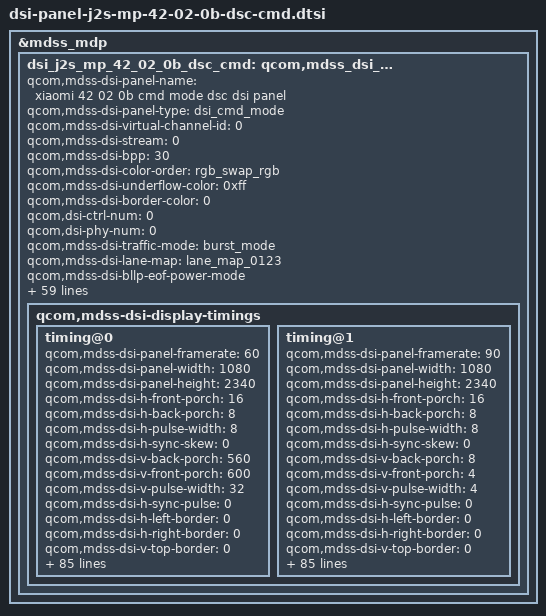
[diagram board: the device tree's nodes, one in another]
&mdss_mdp {
	dsi_j2s_mp_42_02_0b_dsc_cmd: qcom,mdss_dsi_j2s_mp_42_02_0b_dsc_cmd {
		qcom,mdss-dsi-panel-name = "xiaomi 42 02 0b cmd mode dsc dsi panel";
		qcom,mdss-dsi-panel-type = "dsi_cmd_mode";
		qcom,mdss-dsi-virtual-channel-id = <0>;
		qcom,mdss-dsi-stream = <0>;
		qcom,mdss-dsi-bpp = <30>;
		qcom,mdss-dsi-color-order = "rgb_swap_rgb";
		qcom,mdss-dsi-underflow-color = <0xff>;
		qcom,mdss-dsi-border-color = <0>;

		qcom,dsi-ctrl-num = <0>;
		qcom,dsi-phy-num = <0>;

		qcom,mdss-dsi-traffic-mode = "burst_mode";
		qcom,mdss-dsi-lane-map = "lane_map_0123";
		qcom,mdss-dsi-bllp-eof-power-mode;
		qcom,mdss-dsi-bllp-power-mode;
		qcom,mdss-dsi-lane-0-state;
		qcom,mdss-dsi-lane-1-state;
		qcom,mdss-dsi-lane-2-state;
		qcom,mdss-dsi-lane-3-state;
		qcom,mdss-dsi-dma-trigger = "trigger_sw";
		qcom,mdss-dsi-mdp-trigger = "none";
		qcom,mdss-dsi-reset-sequence = <1 1>, <0 1>, <1 10>;
		qcom,mdss-pan-physical-width-dimension = <710>;
		qcom,mdss-pan-physical-height-dimension = <1537>;
		qcom,mdss-dsi-te-pin-select = <1>;
		qcom,mdss-dsi-wr-mem-start = <0x2c>;
		qcom,mdss-dsi-wr-mem-continue = <0x3c>;
		qcom,mdss-dsi-te-dcs-command = <1>;
		qcom,mdss-dsi-te-check-enable;
		qcom,mdss-dsi-te-using-te-pin;
		qcom,mdss-dsi-tx-eot-append;
		qcom,mdss-dsi-lp11-init;

		qcom,mdss-dsi-panel-hdr-enabled;
		qcom,mdss-dsi-panel-hdr-color-primaries = <14500 15500 32000
			17000 15500 30000 8000 3000>;
		qcom,mdss-dsi-panel-peak-brightness = <4200000>;
		qcom,mdss-dsi-panel-blackness-level = <3230>;

		qcom,bl-update-flag = "delay_until_first_frame";

		qcom,esd-check-enabled;
		qcom,mdss-dsi-panel-status-check-mode = "reg_read";
		qcom,mdss-dsi-panel-status-offset-command = [
			39 00 00 00 00 00 05 FF AA 55 A5 81
			15 01 00 00 00 00 02 6F 0F];
		qcom,mdss-dsi-panel-status-command = [
			06 01 00 01 00 00 01 FA
			06 01 00 01 00 00 01 91];
		qcom,mdss-dsi-panel-status-read-length = <1 18>;
		qcom,mdss-dsi-panel-max-error-count = <3>;
		qcom,mdss-dsi-panel-status-value = <0x00>,
				<0xAB 0x28 0x00 0x0C 0xC2 0x00 0x03 0x1C 0x01 0x7E 0x00 0x0F 0x08 0xBB 0x04 0x3D 0x10 0xF0>;
		qcom,mdss-dsi-panel-status-command-state = "dsi_lp_mode";
		qcom,mdss-dsi-panel-status-offset-command-state = "dsi_lp_mode";

		qcom,mdss-dsi-display-timings {
			timing@0{
				qcom,mdss-dsi-panel-framerate = <60>;
				qcom,mdss-dsi-panel-width = <1080>;
				qcom,mdss-dsi-panel-height = <2340>;
				qcom,mdss-dsi-h-front-porch = <16>;
				qcom,mdss-dsi-h-back-porch = <8>;
				qcom,mdss-dsi-h-pulse-width = <8>;
				qcom,mdss-dsi-h-sync-skew = <0>;
				qcom,mdss-dsi-v-back-porch = <560>;
				qcom,mdss-dsi-v-front-porch = <600>;
				qcom,mdss-dsi-v-pulse-width = <32>;
				qcom,mdss-dsi-h-sync-pulse = <0>;
				qcom,mdss-dsi-h-left-border = <0>;
				qcom,mdss-dsi-h-right-border = <0>;
				qcom,mdss-dsi-v-top-border = <0>;
				qcom,mdss-dsi-v-bottom-border = <0>;
				qcom,mdss-dsi-panel-clockrate = <682000000>;
				qcom,mdss-dsi-panel-jitter = <0x5 0x1>;
				qcom,mdss-mdp-transfer-time-us = <9500>;
				qcom,mdss-dsi-on-command = [
					39 00 00 00 00 00 05 3B 00 18 00 18
					39 00 00 00 00 00 02 03 01
					39 00 00 00 00 00 02 90 01
					39 00 00 00 00 00 13 91 89 28 00 0C C2 00 03 1C 01 7E 00 0F 08 BB 04 3D 10 F0
					05 01 00 00 00 00 02 2C 00
					39 00 00 00 00 00 06 F0 55 AA 52 08 00
					39 00 00 00 00 00 04 C0 66 F3 C1
					39 00 00 00 00 00 02 6F 06
					39 01 00 00 00 00 04 B5 2B 0A 32
					39 00 00 00 00 00 02 6F 0B
					39 01 00 00 00 00 04 B5 33 23 2B
					39 00 00 00 00 00 06 F0 55 AA 52 08 01
					39 00 00 00 00 00 02 6F 01
					39 00 00 00 00 00 04 D2 00 22 33
					39 00 00 00 00 00 06 CE 00 00 01 00 04
					39 00 00 00 00 00 08 C3 95 01 92 D0 22 02 00
					39 00 00 00 00 00 02 53 20
					05 00 00 00 00 00 02 35 00
					39 00 00 00 00 00 05 2A 00 00 04 37
					39 01 00 00 00 00 05 2B 00 00 09 23
					39 00 00 00 00 00 05 FF AA 55 A5 81
					39 00 00 00 00 00 02 6F 0F
					39 00 00 00 00 00 02 FD 01
					39 00 00 00 00 00 02 6F 10
					39 00 00 00 00 00 02 FD 41
					39 01 00 00 00 00 02 2F 01
					05 01 00 00 78 00 02 11 00
					05 01 00 00 14 00 02 29 00];
				qcom,mdss-dsi-off-command = [
					05 01 00 00 00 00 02 28 00
					05 01 00 00 78 00 02 10 00];
				qcom,mdss-dsi-on-command-state = "dsi_lp_mode";
				qcom,mdss-dsi-off-command-state = "dsi_lp_mode";

				qcom,mdss-dsi-timing-switch-command = [
					/* Enter 60Hz */
					15 01 00 00 00 00 02 2F 01];
				qcom,mdss-dsi-timing-switch-command-state = "dsi_lp_mode";

				qcom,mdss-dsi-nolp-command = [
					/* close aod backlight */
					15 00 00 00 00 00 02 6F 02
					39 01 00 00 00 00 03 51 00 00
					/* Aod to Normal */
					39 00 00 00 00 00 06 F0 55 AA 52 08 00 /* Set page 0 */
					15 00 00 00 00 00 02 B2 58
					15 00 00 00 00 00 02 65 00
					05 00 00 00 00 00 02 38 00
					05 01 00 00 00 00 02 2C 00];
				qcom,mdss-dsi-nolp-command-state = "dsi_lp_mode";

				qcom,compression-mode = "dsc";
				qcom,mdss-dsc-version = <0x11>;
				qcom,mdss-dsc-scr-version = <0x0>;
				qcom,mdss-dsc-slice-height = <12>;
				qcom,mdss-dsc-slice-width = <1080>;
				qcom,mdss-dsc-slice-per-pkt = <2>;
				qcom,mdss-dsc-bit-per-component = <10>;
				qcom,mdss-dsc-bit-per-pixel = <8>;
				qcom,mdss-dsc-block-prediction-enable;
			};
			timing@1{
				qcom,mdss-dsi-panel-framerate = <90>;
				qcom,mdss-dsi-panel-width = <1080>;
				qcom,mdss-dsi-panel-height = <2340>;
				qcom,mdss-dsi-h-front-porch = <16>;
				qcom,mdss-dsi-h-back-porch = <8>;
				qcom,mdss-dsi-h-pulse-width = <8>;
				qcom,mdss-dsi-h-sync-skew = <0>;
				qcom,mdss-dsi-v-back-porch = <8>;
				qcom,mdss-dsi-v-front-porch = <4>;
				qcom,mdss-dsi-v-pulse-width = <4>;
				qcom,mdss-dsi-h-sync-pulse = <0>;
				qcom,mdss-dsi-h-left-border = <0>;
				qcom,mdss-dsi-h-right-border = <0>;
				qcom,mdss-dsi-v-top-border = <0>;
				qcom,mdss-dsi-v-bottom-border = <0>;
				qcom,mdss-dsi-panel-clockrate = <682000000>;
				qcom,mdss-dsi-panel-jitter = <0x5 0x1>;
				qcom,mdss-mdp-transfer-time-us = <9500>;
				qcom,mdss-dsi-on-command = [
					39 00 00 00 00 00 05 3B 00 18 00 18
					39 00 00 00 00 00 02 03 01
					39 00 00 00 00 00 02 90 01
					39 00 00 00 00 00 13 91 89 28 00 0C C2 00 03 1C 01 7E 00 0F 08 BB 04 3D 10 F0
					05 01 00 00 00 00 02 2C 00
					39 00 00 00 00 00 06 F0 55 AA 52 08 00
					39 00 00 00 00 00 04 C0 66 F3 C1
					39 00 00 00 00 00 02 6F 06
					39 01 00 00 00 00 04 B5 2B 0A 32
					39 00 00 00 00 00 02 6F 0B
					39 01 00 00 00 00 04 B5 33 23 2B
					39 00 00 00 00 00 06 F0 55 AA 52 08 01
					39 00 00 00 00 00 04 D2 00 22 33
					39 00 00 00 00 00 06 CE 00 00 01 00 04
					39 00 00 00 00 00 08 C3 95 01 92 D0 22 02 00
					39 00 00 00 00 00 02 53 20
					05 00 00 00 00 00 02 35 00
					39 00 00 00 00 00 05 2A 00 00 04 37
					39 01 00 00 00 00 05 2B 00 00 09 23
					39 00 00 00 00 00 05 FF AA 55 A5 81
					39 00 00 00 00 00 02 6F 0F
					39 00 00 00 00 00 02 FD 01
					39 00 00 00 00 00 02 6F 10
					39 00 00 00 00 00 02 FD 41
					39 01 00 00 00 00 02 2F 02
					05 01 00 00 78 00 02 11 00
					05 01 00 00 14 00 02 29 00];
				qcom,mdss-dsi-off-command = [
					05 01 00 00 00 00 02 28 00
					05 01 00 00 78 00 02 10 00];
				qcom,mdss-dsi-on-command-state = "dsi_lp_mode";
				qcom,mdss-dsi-off-command-state = "dsi_lp_mode";

				qcom,mdss-dsi-timing-switch-command = [
					/* Enter 90Hz */
					15 01 00 00 00 00 02 2F 02];
				qcom,mdss-dsi-timing-switch-command-state = "dsi_lp_mode";

				qcom,mdss-dsi-nolp-command = [
					/* close aod backlight */
					15 00 00 00 00 00 02 6F 02
					39 01 00 00 00 00 03 51 00 00
					/* Aod to Normal */
					39 00 00 00 00 00 06 F0 55 AA 52 08 00 /* Set page 0 */
					15 00 00 00 00 00 02 B2 58
					15 00 00 00 00 00 02 65 00
					05 00 00 00 00 00 02 38 00
					05 01 00 00 00 00 02 2C 00
					/* Enter 90Hz */
					15 01 00 00 00 00 02 2F 02];
				qcom,mdss-dsi-nolp-command-state = "dsi_lp_mode";

				qcom,compression-mode = "dsc";
				qcom,mdss-dsc-version = <0x11>;
				qcom,mdss-dsc-scr-version = <0x0>;
				qcom,mdss-dsc-slice-height = <12>;
				qcom,mdss-dsc-slice-width = <1080>;
				qcom,mdss-dsc-slice-per-pkt = <2>;
				qcom,mdss-dsc-bit-per-component = <10>;
				qcom,mdss-dsc-bit-per-pixel = <8>;
				qcom,mdss-dsc-block-prediction-enable;
			};
		};
	};
};

&dsi_j2s_mp_42_02_0b_dsc_cmd {
	mi,panel-id = <0x4A32 0x00420201>;
	mi,feature-enabled;
	mi,mdss-dsi-bl-dcs-big-endian-type;
	mi,mdss-dsi-panel-hbm-51-ctrl-flag;
	mi,mdss-dsi-panel-hbm-off-51-index = <1>;
	mi,mdss-dsi-panel-fod-off-51-index = <1>;
	mi,mdss-dsi-panel-disp-rate-gpio = <&tlmm 50 0>;
	/* IRQF_ONESHOT | IRQF_TRIGGER_RISING */
	/* trig-flags: falling-0x0002 rasing-0x0001 */
	mi,esd-err-irq-gpio = <&tlmm 51 0x2002>;

	/* White Color Coordinate */
	mi,mdss-dsi-white-point-read-enabled;
	mi,mdss-dsi-white-point-register-read-length = <8>;
	mi,mdss-dsi-white-point-info-index = <0>;
	mi,mdss-dsi-white-point-info-length = <8>;

	mi,mdss-dsi-panel-dc-type = <0>;

	mi,mdss-panel-on-dimming-delay = <120>;

	mi,mdss-dsi-panel-fod-dimlayer-enabled;

	mi,mdss-dsi-dimlayer-brightness-alpha-lut-item-count = <21>;
	mi,mdss-dsi-dimlayer-brightness-alpha-lut =
	/* brightness  alpha */
		<0          0xFF
		 4          0xEB
		 8          0xEA
		 12         0xE9
		 13         0xE8
		 20         0xE5
		 24         0xE3
		 30         0xE0
		 68         0xD0
		 133        0xC0
		 218        0xB0
		 328        0xA0
		 486        0x90
		 642        0x80
		 832        0x70
		 1043       0x60
		 1267       0x50
		 1500       0x40
		 1770       0x30
		 2000       0x24
		 2047       0x21>;

	qcom,mdss-dsi-display-timings {
		timing@0{
			mi,mdss-dsi-doze-hbm-command = [
				/* Enter 60Hz */
				15 01 00 00 00 00 02 2F 01
				/* AOD Mode On */
				39 00 00 00 00 00 06 F0 55 AA 52 08 00
				15 00 00 00 00 00 02 B2 08
				05 00 00 00 00 00 02 39 00
				15 00 00 00 00 00 02 65 01
				05 01 00 00 00 00 02 2C 00
				/* 60 nit*/
				15 00 00 00 00 00 02 6F 02
				39 01 00 00 00 00 03 51 0F FF];
			mi,mdss-dsi-doze-lbm-command = [
				/* Enter 60Hz */
				15 01 00 00 00 00 02 2F 01
				/* AOD Mode On */
				39 00 00 00 00 00 06 F0 55 AA 52 08 00
				15 00 00 00 00 00 02 B2 08
				05 00 00 00 00 00 02 39 00
				15 00 00 00 00 00 02 65 01
				05 01 00 00 00 00 02 2C 00
				/* 5 nit */
				15 00 00 00 00 00 02 6F 02
				39 01 00 00 00 00 03 51 01 55];
			mi,mdss-dsi-doze-hbm-command-state = "dsi_lp_mode";
			mi,mdss-dsi-doze-lbm-command-state = "dsi_lp_mode";

			mi,mdss-dsi-hbm-on-command = [
				/* Dimming On */
				15 00 00 00 00 00 02 53 28
				/* HBM Mode 800 nit */
				39 01 00 00 00 00 05 51 0F FF 00 00];
			mi,mdss-dsi-hbm-off-command = [
				/* Dimming On */
				15 00 00 00 00 00 02 53 28
				/* Normal Mode */
				/* parameter will be updated base on last brightness */
				39 01 00 00 00 00 05 51 07 FF 00 00];
			mi,mdss-dsi-hbm-on-command-state = "dsi_lp_mode";
			mi,mdss-dsi-hbm-off-command-state = "dsi_lp_mode";

			/* aod mode -> hbm on for fingerprint unlock */
			mi,mdss-dsi-hbm-fod-on-command = [
				/* Dimming Off */
				15 00 00 00 00 00 02 53 20
				/* HBM Mode 700 nit */
				39 01 00 00 00 00 05 51 0F 8F 00 00
				/* Aod to Normal */
				39 00 00 00 00 00 06 F0 55 AA 52 08 00 /* Set page 0 */
				15 00 00 00 00 00 02 B2 58
				15 00 00 00 00 00 02 65 00
				05 00 00 00 00 00 02 38 00
				05 01 00 00 00 00 02 2C 00];
			mi,mdss-dsi-hbm-fod-off-command = [
				/* Dimming Off */
				15 00 00 00 00 00 02 53 20
				/* Normal Mode */
				/* parameter will be updated base on last brightness */
				39 01 00 00 00 00 05 51 07 FF 00 00];
			mi,mdss-dsi-hbm-fod-on-command-state = "dsi_lp_mode";
			mi,mdss-dsi-hbm-fod-off-command-state = "dsi_lp_mode";

			mi,mdss-dsi-hbm-hdr-on-command = [
				/* VI Setting voltage -3.5V */
				39 01 00 00 00 00 06 F0 55 AA 52 08 01 /* Set page 1 */
				39 00 00 00 00 00 09 B9 1F 1F 1F 1F 1F 1F 1F 1F
				/* Dimming On */
				15 00 00 00 00 00 02 53 28
				/* HBM Mode 800 nit */
				39 01 00 00 00 00 05 51 0F FF 00 00
				/* ELVSS SWIRE =-4.5V */
				15 01 00 00 00 00 02 6F 07
				15 01 00 00 00 00 02 B5 0A];
			mi,mdss-dsi-hbm-hdr-off-command = [
				/* Dimming On */
				15 01 00 00 00 00 02 53 28
				/* Normal Mode */
				/* parameter will be updated base on last brightness */
				39 01 00 00 00 00 05 51 07 FF 00 00];
			mi,mdss-dsi-hbm-hdr-on-command-state = "dsi_lp_mode";
			mi,mdss-dsi-hbm-hdr-off-command-state = "dsi_lp_mode";

			mi,mdss-dsi-dimmingon-command = [15 01 00 00 00 00 02 53 28];
			mi,mdss-dsi-dimmingon-command-state = "dsi_lp_mode";
			mi,mdss-dsi-dimmingoff-command = [15 01 00 00 00 00 02 53 20];
			mi,mdss-dsi-dimmingoff-command-state = "dsi_lp_mode";

			mi,mdss-dsi-white-point-read-command = [06 01 00 00 01 00 02 DF 00];
			mi,mdss-dsi-white-point-read-command-state = "dsi_lp_mode";

			mi,mdss-dsi-switch-page4-command = [
				/* Set page 4 */
				39 01 00 00 00 00 06 F0 55 AA 52 08 04];
			mi,mdss-dsi-dc-read-command = [
				/* Read DC_LUT */
				06 01 00 00 00 00 02 D2 00];
			mi,mdss-dsi-switch-page4-command-state = "dsi_lp_mode";
			mi,mdss-dsi-dc-read-command-state = "dsi_lp_mode";

			mi,mdss-dsi-dc-on-command = [
				39 00 00 00 00 00 06 F0 55 AA 52 08 00 /* Set page 0 */
				15 00 00 00 00 00 02 B2 D8
				15 00 00 00 00 00 02 6F 0F
				39 00 00 00 00 00 03 B2 00 00
				39 00 00 00 00 00 25 B3 00 00 00 00 00 00 00 00 00 00 00 00 00 00 00 00 00 00 00 00 00 00 00 00 00 00 00 00 00 00 00 00 07 FF 0F FF
				39 00 00 00 00 00 06 F0 55 AA 52 08 04 /* Set page 4 */
				39 01 00 00 00 00 4C D2
					12 1F 1F 12 10 19 1F 1F 19 20 30 30 30 30 2B 3F 3F 3F 3F 38 5F 5F 5F 5A 60
					2F 20 20 30 0D 19 25 25 23 25 3F 3F 3F 3F 2F 45 45 45 45 45 65 65 65 6F 68
					1A 20 20 20 08 1F 1F 1F 1F 10 2F 2F 2F 2F 24 3F 3F 3F 3F 38 9F 88 74 5F 60
				39 01 00 00 00 00 4C D4
					1F 20 20 20 14 20 30 30 1A 20 3F 3F 3F 30 2B 5F 5F 5F 50 3B 5F 5F 5F 5F 6F
					40 2D 2D 2D 0E 20 35 35 30 20 36 36 36 36 36 58 58 58 58 4A 6F 6F 6F 6F 7F
					10 1B 1B 1B 0D 25 25 25 25 18 36 36 36 36 2B 4F 4F 4F 4F 3B 5F 5F 5F 5F 5F];
			mi,mdss-dsi-dc-on-command-state = "dsi_lp_mode";
			mi,mdss-dsi-dc-off-command = [
				39 00 00 00 00 00 06 F0 55 AA 52 08 00 /* Set page 0 */
				15 00 00 00 00 00 02 B2 58
				15 00 00 00 00 00 02 6F 0F
				39 00 00 00 00 00 03 B2 20 20
				39 00 00 00 00 00 25 B3 00 08 00 21 00 21 00 52 00 52 00 76 00 76 00 AE 00 AE 01 0E 01 0E 01 C2 01 C2 03 33 03 33 07 FF 07 FF 0F FF
				39 00 00 00 00 00 06 F0 55 AA 52 08 04 /* Set page 4 */
				39 01 00 00 00 00 4C D2
					98 60 30 1F 10 98 40 40 1F 20 60 48 44 30 2B 70 48 70 3F 38 3F 78 74 5F 60
					98 60 4A 30 0D 98 95 50 20 25 68 60 54 3F 2F FA 68 74 45 45 95 88 84 65 68
					98 40 40 20 08 98 40 40 1F 10 68 38 44 2F 24 88 38 64 3F 38 9F 88 74 5F 60
				39 01 00 00 00 00 4C D4
					FF 88 50 20 14 FF 58 50 30 20 FF 60 5F 3F 2B 7F 72 6F 5F 3B BF 92 7F 5F 6F
					FF 8A 5F 2D 0E FF B0 9F 50 20 FF 95 62 50 36 FF 65 7F 58 4A F5 A8 8F 6F 7F
					FF 88 38 1B 0D FF 48 28 25 18 FF 46 42 36 2B B0 82 5F 4F 3B 6F 82 7F 5F 5F];
			mi,mdss-dsi-dc-off-command-state = "dsi_lp_mode";

			mi,mdss-dsi-aod-to-dc-on-command = [
				39 00 00 00 00 00 06 F0 55 AA 52 08 00 /* Set page 0 */
				15 00 00 00 00 00 02 B2 D8
				15 00 00 00 00 00 02 6F 0F
				39 00 00 00 00 00 03 B2 00 00
				39 00 00 00 00 00 25 B3 00 00 00 00 00 00 00 00 00 00 00 00 00 00 00 00 00 00 00 00 00 00 00 00 00 00 00 00 00 00 00 00 07 FF 0F FF
				39 00 00 00 00 00 06 F0 55 AA 52 08 04 /* Set page 4 */
				39 01 00 00 00 00 4C D2
					12 1F 1F 12 10 19 1F 1F 19 20 30 30 30 30 2B 3F 3F 3F 3F 38 5F 5F 5F 5A 60
					2F 20 20 30 0D 19 25 25 23 25 3F 3F 3F 3F 2F 45 45 45 45 45 65 65 65 6F 68
					1A 20 20 20 08 1F 1F 1F 1F 10 2F 2F 2F 2F 24 3F 3F 3F 3F 38 9F 88 74 5F 60
				39 01 00 00 00 00 4C D4
					1F 20 20 20 14 20 30 30 1A 20 3F 3F 3F 30 2B 5F 5F 5F 50 3B 5F 5F 5F 5F 6F
					40 2D 2D 2D 0E 20 35 35 30 20 36 36 36 36 36 58 58 58 58 4A 6F 6F 6F 6F 7F
					10 1B 1B 1B 0D 25 25 25 25 18 36 36 36 36 2B 4F 4F 4F 4F 3B 5F 5F 5F 5F 5F];
			mi,mdss-dsi-aod-to-dc-on-command-state = "dsi_lp_mode";
		};
		timing@1{
			mi,mdss-dsi-doze-hbm-command = [
				/* Enter 60Hz */
				15 01 00 00 00 00 02 2F 01
				/* AOD Mode On */
				39 00 00 00 00 00 06 F0 55 AA 52 08 00
				15 00 00 00 00 00 02 B2 08
				05 00 00 00 00 00 02 39 00
				15 00 00 00 00 00 02 65 01
				05 01 00 00 00 00 02 2C 00
				/* 60 nit */
				15 00 00 00 00 00 02 6F 02
				39 01 00 00 00 00 03 51 0F FF];
			mi,mdss-dsi-doze-lbm-command = [
				/* Enter 60Hz */
				15 01 00 00 00 00 02 2F 01
				/* AOD Mode On */
				39 00 00 00 00 00 06 F0 55 AA 52 08 00
				15 00 00 00 00 00 02 B2 08
				05 00 00 00 00 00 02 39 00
				15 00 00 00 00 00 02 65 01
				05 01 00 00 00 00 02 2C 00
				/* 5 nit */
				15 00 00 00 00 00 02 6F 02
				39 01 00 00 00 00 03 51 01 55];
			mi,mdss-dsi-doze-hbm-command-state = "dsi_lp_mode";
			mi,mdss-dsi-doze-lbm-command-state = "dsi_lp_mode";

			mi,mdss-dsi-hbm-on-command = [
				/* Dimming On */
				15 00 00 00 00 00 02 53 28
				/* HBM Mode 800 nit */
				39 01 00 00 00 00 05 51 0F FF 00 00];
			mi,mdss-dsi-hbm-off-command = [
				/* Dimming On */
				15 00 00 00 00 00 02 53 28
				/* Normal Mode */
				/* parameter will be updated base on last brightness */
				39 01 00 00 00 00 05 51 07 FF 00 00];
			mi,mdss-dsi-hbm-on-command-state = "dsi_lp_mode";
			mi,mdss-dsi-hbm-off-command-state = "dsi_lp_mode";

			/* aod mode -> hbm on for fingerprint unlock */
			mi,mdss-dsi-hbm-fod-on-command = [
				/* Dimming Off */
				15 00 00 00 00 00 02 53 20
				/* HBM Mode 700 nit */
				39 01 00 00 00 00 05 51 0F 8F 00 00
				/* Aod to Normal */
				39 00 00 00 00 00 06 F0 55 AA 52 08 00 /* Set page 0 */
				15 00 00 00 00 00 02 B2 58
				15 00 00 00 00 00 02 65 00
				05 00 00 00 00 00 02 38 00
				05 01 00 00 00 00 02 2C 00
				/* Enter 90Hz */
				15 01 00 00 00 00 02 2F 02];
			mi,mdss-dsi-hbm-fod-off-command = [
				/* Dimming Off */
				15 00 00 00 00 00 02 53 20
				/* Normal Mode */
				/* parameter will be updated base on last brightness */
				39 01 00 00 00 00 05 51 07 FF 00 00];
			mi,mdss-dsi-hbm-fod-on-command-state = "dsi_lp_mode";
			mi,mdss-dsi-hbm-fod-off-command-state = "dsi_lp_mode";

			mi,mdss-dsi-hbm-hdr-on-command = [
				/* VI Setting voltage -3.5V */
				39 01 00 00 00 00 06 F0 55 AA 52 08 01 /* Set page 1 */
				39 00 00 00 00 00 09 B9 1F 1F 1F 1F 1F 1F 1F 1F
				/* Dimming On */
				15 00 00 00 00 00 02 53 28
				/* HBM Mode 800 nit */
				39 01 00 00 00 00 05 51 0F FF 00 00
				/* ELVSS SWIRE =-4.5V */
				15 01 00 00 00 00 02 6F 07
				15 01 00 00 00 00 02 B5 0A];
			mi,mdss-dsi-hbm-hdr-off-command = [
				/* Dimming On */
				15 01 00 00 00 00 02 53 28
				/* Normal Mode */
				/* parameter will be updated base on last brightness */
				39 01 00 00 00 00 05 51 07 FF 00 00];
			mi,mdss-dsi-hbm-hdr-on-command-state = "dsi_lp_mode";
			mi,mdss-dsi-hbm-hdr-off-command-state = "dsi_lp_mode";

			mi,mdss-dsi-dimmingon-command = [15 01 00 00 00 00 02 53 28];
			mi,mdss-dsi-dimmingon-command-state = "dsi_lp_mode";
			mi,mdss-dsi-dimmingoff-command = [15 01 00 00 00 00 02 53 20];
			mi,mdss-dsi-dimmingoff-command-state = "dsi_lp_mode";

			mi,mdss-dsi-white-point-read-command = [06 01 00 00 01 00 02 DF 00];
			mi,mdss-dsi-white-point-read-command-state = "dsi_lp_mode";

			mi,mdss-dsi-switch-page4-command = [
				/* Set page 4 */
				39 01 00 00 00 00 06 F0 55 AA 52 08 04];
			mi,mdss-dsi-dc-read-command = [
				/* Read DC_LUT */
				06 01 00 00 00 00 02 D2 00];
			mi,mdss-dsi-switch-page4-command-state = "dsi_lp_mode";
			mi,mdss-dsi-dc-read-command-state = "dsi_lp_mode";

			mi,mdss-dsi-dc-on-command = [
				39 00 00 00 00 00 06 F0 55 AA 52 08 00 /* Set page 0 */
				15 00 00 00 00 00 02 B2 D8
				15 00 00 00 00 00 02 6F 0F
				39 00 00 00 00 00 03 B2 00 00
				39 00 00 00 00 00 25 B3 00 00 00 00 00 00 00 00 00 00 00 00 00 00 00 00 00 00 00 00 00 00 00 00 00 00 00 00 00 00 00 00 07 FF 0F FF
				39 00 00 00 00 00 06 F0 55 AA 52 08 04 /* Set page 4 */
				39 01 00 00 00 00 4C D2
					12 1F 1F 12 10 19 1F 1F 19 20 30 30 30 30 2B 3F 3F 3F 3F 38 5F 5F 5F 5A 60
					2F 20 20 30 0D 19 25 25 23 25 3F 3F 3F 3F 2F 45 45 45 45 45 65 65 65 6F 68
					1A 20 20 20 08 1F 1F 1F 1F 10 2F 2F 2F 2F 24 3F 3F 3F 3F 38 9F 88 74 5F 60
				39 01 00 00 00 00 4C D4
					1F 20 20 20 14 20 30 30 1A 20 3F 3F 3F 30 2B 5F 5F 5F 50 3B 5F 5F 5F 5F 6F
					40 2D 2D 2D 0E 20 35 35 30 20 36 36 36 36 36 58 58 58 58 4A 6F 6F 6F 6F 7F
					10 1B 1B 1B 0D 25 25 25 25 18 36 36 36 36 2B 4F 4F 4F 4F 3B 5F 5F 5F 5F 5F];
			mi,mdss-dsi-dc-on-command-state = "dsi_lp_mode";
			mi,mdss-dsi-dc-off-command = [
				39 00 00 00 00 00 06 F0 55 AA 52 08 00 /* Set page 0 */
				15 00 00 00 00 00 02 B2 58
				15 00 00 00 00 00 02 6F 0F
				39 00 00 00 00 00 03 B2 20 20
				39 00 00 00 00 00 25 B3 00 08 00 21 00 21 00 52 00 52 00 76 00 76 00 AE 00 AE 01 0E 01 0E 01 C2 01 C2 03 33 03 33 07 FF 07 FF 0F FF
				39 00 00 00 00 00 06 F0 55 AA 52 08 04 /* Set page 4 */
				39 01 00 00 00 00 4C D2
					98 60 30 1F 10 98 40 40 1F 20 60 48 44 30 2B 70 48 70 3F 38 3F 78 74 5F 60
					98 60 4A 30 0D 98 95 50 20 25 68 60 54 3F 2F FA 68 74 45 45 95 88 84 65 68
					98 40 40 20 08 98 40 40 1F 10 68 38 44 2F 24 88 38 64 3F 38 9F 88 74 5F 60
				39 01 00 00 00 00 4C D4
					FF 88 50 20 14 FF 58 50 30 20 FF 60 5F 3F 2B 7F 72 6F 5F 3B BF 92 7F 5F 6F
					FF 8A 5F 2D 0E FF B0 9F 50 20 FF 95 62 50 36 FF 65 7F 58 4A F5 A8 8F 6F 7F
					FF 88 38 1B 0D FF 48 28 25 18 FF 46 42 36 2B B0 82 5F 4F 3B 6F 82 7F 5F 5F];
			mi,mdss-dsi-dc-off-command-state = "dsi_lp_mode";

			mi,mdss-dsi-aod-to-dc-on-command = [
				39 00 00 00 00 00 06 F0 55 AA 52 08 00 /* Set page 0 */
				15 00 00 00 00 00 02 B2 D8
				15 00 00 00 00 00 02 6F 0F
				39 00 00 00 00 00 03 B2 00 00
				39 00 00 00 00 00 25 B3 00 00 00 00 00 00 00 00 00 00 00 00 00 00 00 00 00 00 00 00 00 00 00 00 00 00 00 00 00 00 00 00 07 FF 0F FF
				39 00 00 00 00 00 06 F0 55 AA 52 08 04 /* Set page 4 */
				39 01 00 00 00 00 4C D2
					12 1F 1F 12 10 19 1F 1F 19 20 30 30 30 30 2B 3F 3F 3F 3F 38 5F 5F 5F 5A 60
					2F 20 20 30 0D 19 25 25 23 25 3F 3F 3F 3F 2F 45 45 45 45 45 65 65 65 6F 68
					1A 20 20 20 08 1F 1F 1F 1F 10 2F 2F 2F 2F 24 3F 3F 3F 3F 38 9F 88 74 5F 60
				39 01 00 00 00 00 4C D4
					1F 20 20 20 14 20 30 30 1A 20 3F 3F 3F 30 2B 5F 5F 5F 50 3B 5F 5F 5F 5F 6F
					40 2D 2D 2D 0E 20 35 35 30 20 36 36 36 36 36 58 58 58 58 4A 6F 6F 6F 6F 7F
					10 1B 1B 1B 0D 25 25 25 25 18 36 36 36 36 2B 4F 4F 4F 4F 3B 5F 5F 5F 5F 5F];
			mi,mdss-dsi-aod-to-dc-on-command-state = "dsi_lp_mode";
		};
	};
};

